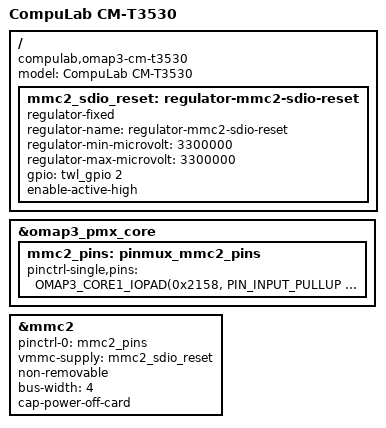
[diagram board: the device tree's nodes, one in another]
/*
 * Support for CompuLab CM-T3530
 */
/dts-v1/;

#include "omap34xx.dtsi"
#include "omap3-cm-t3x30.dtsi"

/ {
	model = "CompuLab CM-T3530";
	compatible = "compulab,omap3-cm-t3530", "ti,omap34xx", "ti,omap3";

	/* Regulator to trigger the reset signal of the Wifi module */
	mmc2_sdio_reset: regulator-mmc2-sdio-reset {
		compatible = "regulator-fixed";
		regulator-name = "regulator-mmc2-sdio-reset";
		regulator-min-microvolt = <3300000>;
		regulator-max-microvolt = <3300000>;
		gpio = <&twl_gpio 2 GPIO_ACTIVE_HIGH>;
		enable-active-high;
	};
};

&omap3_pmx_core {
	mmc2_pins: pinmux_mmc2_pins {
		pinctrl-single,pins = <
			OMAP3_CORE1_IOPAD(0x2158, PIN_INPUT_PULLUP | MUX_MODE0)		/* sdmmc2_clk.sdmmc2_clk */
			OMAP3_CORE1_IOPAD(0x215a, PIN_INPUT_PULLUP | MUX_MODE0)		/* sdmmc2_cmd.sdmmc2_cmd */
			OMAP3_CORE1_IOPAD(0x215c, PIN_INPUT_PULLUP | MUX_MODE0)		/* sdmmc2_dat0.sdmmc2_dat0 */
			OMAP3_CORE1_IOPAD(0x215e, PIN_INPUT_PULLUP | MUX_MODE0)		/* sdmmc2_dat1.sdmmc2_dat1 */
			OMAP3_CORE1_IOPAD(0x2160, PIN_INPUT_PULLUP | MUX_MODE0)		/* sdmmc2_dat2.sdmmc2_dat2 */
			OMAP3_CORE1_IOPAD(0x2162, PIN_INPUT_PULLUP | MUX_MODE0)		/* sdmmc2_dat3.sdmmc2_dat3 */
			OMAP3_CORE1_IOPAD(0x2164, PIN_OUTPUT | MUX_MODE1)		/* sdmmc2_dat4.sdmmc2_dir_dat0 */
			OMAP3_CORE1_IOPAD(0x2166, PIN_OUTPUT | MUX_MODE1)		/* sdmmc2_dat5.sdmmc2_dir_dat1 */
			OMAP3_CORE1_IOPAD(0x2168, PIN_OUTPUT | MUX_MODE1)		/* sdmmc2_dat6.sdmmc2_dir_cmd */
			OMAP3_CORE1_IOPAD(0x216a, PIN_INPUT | MUX_MODE1)		/* sdmmc2_dat7.sdmmc2_clkin */
		>;
	};
};

&mmc2 {
	pinctrl-names = "default";
	pinctrl-0 = <&mmc2_pins>;
	vmmc-supply = <&mmc2_sdio_reset>;
	non-removable;
	bus-width = <4>;
	cap-power-off-card;
};
